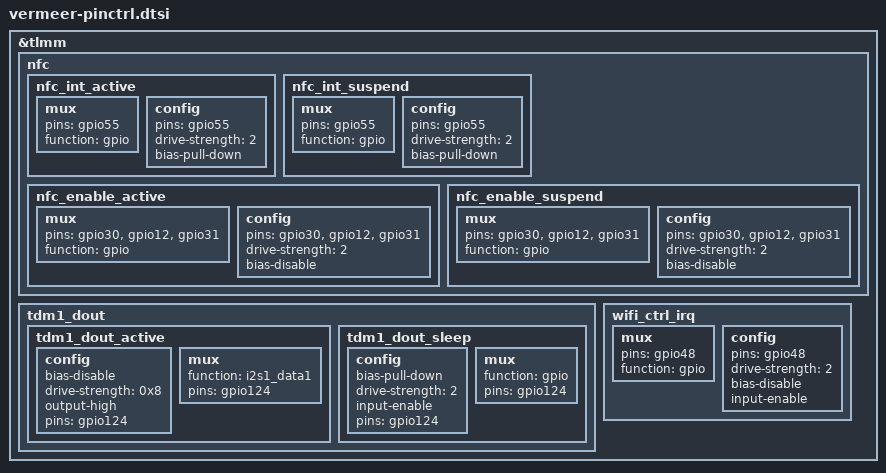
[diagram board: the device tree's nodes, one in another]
/*for vermeer pinctrl */
&tlmm {
	nfc {
		nfc_int_active: nfc_int_active {
			/* active state */
			mux {
				/* NFC Read Interrupt */
				pins = "gpio55";
				function = "gpio";
			};

			config {
				pins = "gpio55";
				drive-strength = <2>; /* 2 MA */
				bias-pull-down;
			};
		};

		nfc_int_suspend: nfc_int_suspend {
			/* sleep state */
			mux {
				/* NFC Read Interrupt */
				pins = "gpio55";
				function = "gpio";
			};

			config {
				pins = "gpio55";
				drive-strength = <2>; /* 2 MA */
				bias-pull-down;
			};
		};

		nfc_enable_active: nfc_enable_active {
			mux {
				/* Enable, Firmware and Clock request gpios */
				pins = "gpio30", "gpio12", "gpio31";
				function = "gpio";
			};

			config {
				pins = "gpio30", "gpio12", "gpio31";
				drive-strength = <2>; /* 2 MA */
				bias-disable;
			};
		};

		nfc_enable_suspend: nfc_enable_suspend {
			mux {
				pins = "gpio30", "gpio12", "gpio31";
				function = "gpio";
			};

			config {
				pins = "gpio30", "gpio12", "gpio31";
				drive-strength = <2>; /* 2 MA */
				bias-disable;
			};
		};
	};

	tdm1_dout {
		tdm1_dout_active: tdm1_dout_active {
			config {
				bias-disable;
				drive-strength = <0x8>;
				output-high;
				pins = "gpio124";
			};

			mux {
				function = "i2s1_data1";
				pins = "gpio124";
			};
		};

		tdm1_dout_sleep: tdm1_dout_sleep {
			config {
				bias-pull-down;
				drive-strength = <2>; /* 2 MA */
				input-enable;
				pins = "gpio124";
			};

			mux {
				function = "gpio";
				pins = "gpio124";
			};
		};
	};

	wifi_ctrl_irq: wifi_ctrl_irq {
		mux {
			pins = "gpio48";
			function = "gpio";
		};

		config {
			pins = "gpio48";
			drive-strength = <2>;   /* 2 mA */
			bias-disable;
			input-enable;
		};
	}; //wifi
};
